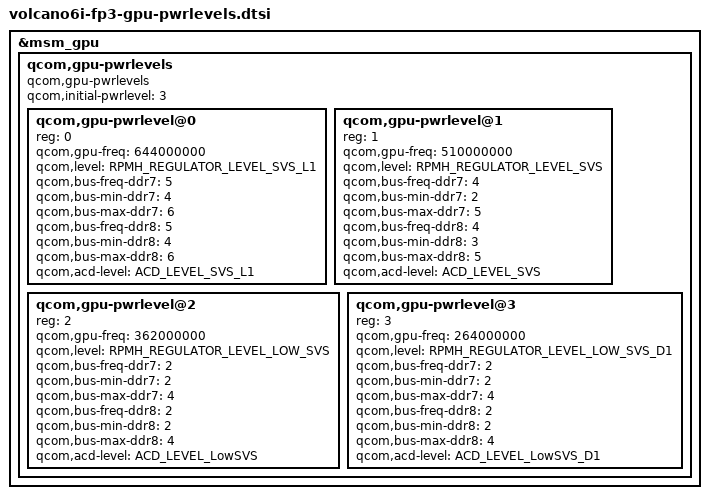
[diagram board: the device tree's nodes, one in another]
&msm_gpu {
	/delete-property/ qcom,gpu-speed-bin;
	/delete-property/ qcom,initial-pwrlevel;
	/delete-node/ qcom,gpu-pwrlevels;
	/delete-node/ qcom,gpu-pwrlevel-bins;

	/* GPU power levels */
	qcom,gpu-pwrlevels {
			#address-cells = <1>;
			#size-cells = <0>;

			qcom,initial-pwrlevel = <3>;
			compatible = "qcom,gpu-pwrlevels";

			qcom,gpu-pwrlevel@0 {
				reg = <0>;
				qcom,gpu-freq = <644000000>;
				qcom,level = <RPMH_REGULATOR_LEVEL_SVS_L1>;

				qcom,bus-freq-ddr7 = <5>;
				qcom,bus-min-ddr7 = <4>;
				qcom,bus-max-ddr7 = <6>;

				qcom,bus-freq-ddr8 = <5>;
				qcom,bus-min-ddr8 = <4>;
				qcom,bus-max-ddr8 = <6>;

				qcom,acd-level = <ACD_LEVEL_SVS_L1>;
			};

			qcom,gpu-pwrlevel@1 {
				reg = <1>;
				qcom,gpu-freq = <510000000>;
				qcom,level = <RPMH_REGULATOR_LEVEL_SVS>;

				qcom,bus-freq-ddr7 = <4>;
				qcom,bus-min-ddr7 = <2>;
				qcom,bus-max-ddr7 = <5>;

				qcom,bus-freq-ddr8 = <4>;
				qcom,bus-min-ddr8 = <3>;
				qcom,bus-max-ddr8 = <5>;

				qcom,acd-level = <ACD_LEVEL_SVS>;
			};

			qcom,gpu-pwrlevel@2 {
				reg = <2>;
				qcom,gpu-freq = <362000000>;
				qcom,level = <RPMH_REGULATOR_LEVEL_LOW_SVS>;

				qcom,bus-freq-ddr7 = <2>;
				qcom,bus-min-ddr7 = <2>;
				qcom,bus-max-ddr7 = <4>;

				qcom,bus-freq-ddr8 = <2>;
				qcom,bus-min-ddr8 = <2>;
				qcom,bus-max-ddr8 = <4>;

				qcom,acd-level = <ACD_LEVEL_LowSVS>;
			};

			qcom,gpu-pwrlevel@3 {
				reg = <3>;
				qcom,gpu-freq = <264000000>;
				qcom,level = <RPMH_REGULATOR_LEVEL_LOW_SVS_D1>;

				qcom,bus-freq-ddr7 = <2>;
				qcom,bus-min-ddr7 = <2>;
				qcom,bus-max-ddr7 = <4>;

				qcom,bus-freq-ddr8 = <2>;
				qcom,bus-min-ddr8 = <2>;
				qcom,bus-max-ddr8 = <4>;

				qcom,acd-level = <ACD_LEVEL_LowSVS_D1>;
			};
	};
};
